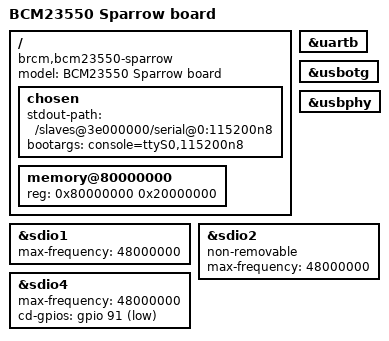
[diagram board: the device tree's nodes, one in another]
/dts-v1/;
#include <dt-bindings/gpio/gpio.h>
#include "bcm23550.dtsi"
/ {
	model = "BCM23550 Sparrow board";
	compatible = "brcm,bcm23550-sparrow", "brcm,bcm23550";
	chosen {
		stdout-path = "/slaves@3e000000/serial@0:115200n8";
		bootargs = "console=ttyS0,115200n8";
	};
	memory@80000000 {
		device_type = "memory";
		reg = <0x80000000 0x20000000>;  
	};
};
&uartb {
	status = "okay";
};
&usbotg {
	status = "okay";
};
&usbphy {
	status = "okay";
};
&sdio1 {
	max-frequency = <48000000>;
	status = "okay";
};
&sdio2 {
	non-removable;
	max-frequency = <48000000>;
	status = "okay";
};
&sdio4 {
	max-frequency = <48000000>;
	cd-gpios = <&gpio 91 GPIO_ACTIVE_LOW>;
	status = "okay";
};
